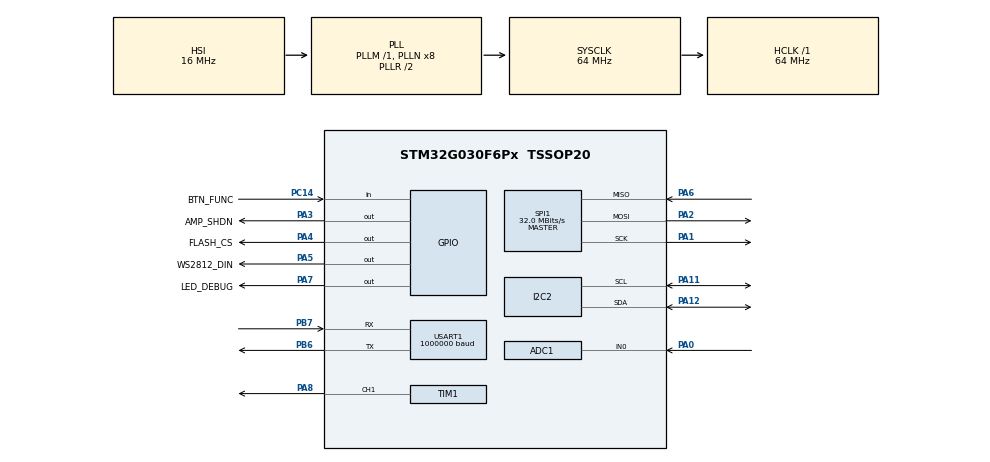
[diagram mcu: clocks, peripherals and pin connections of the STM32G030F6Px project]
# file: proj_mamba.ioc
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ADC1.Channel-0\#ChannelRegularConversion=ADC_CHANNEL_0
ADC1.NbrOfConversionFlag=1
ADC1.Rank-0\#ChannelRegularConversion=1
ADC1.SamplingTime-0\#ChannelRegularConversion=ADC_SAMPLINGTIME_COMMON_1
ADC1.SamplingTimeCommon1=ADC_SAMPLETIME_160CYCLES_5
ADC1.SelectedChannel=ADC_CHANNEL_0
ADC1.master=1
Dma.Request0=SPI1_RX
Dma.Request1=SPI1_TX
Dma.Request2=USART1_RX
Dma.Request3=USART1_TX
Dma.SPI1_RX.0.Direction=DMA_PERIPH_TO_MEMORY
Dma.SPI1_RX.0.EventEnable=DISABLE
Dma.SPI1_RX.0.Instance=DMA1_Channel1
Dma.SPI1_RX.0.MemDataAlignment=DMA_MDATAALIGN_BYTE
Dma.SPI1_RX.0.MemInc=DMA_MINC_ENABLE
Dma.SPI1_RX.0.Mode=DMA_NORMAL
Dma.SPI1_RX.0.PeriphDataAlignment=DMA_PDATAALIGN_BYTE
Dma.SPI1_RX.0.PeriphInc=DMA_PINC_DISABLE
Dma.SPI1_RX.0.Polarity=HAL_DMAMUX_REQ_GEN_RISING
Dma.SPI1_RX.0.Priority=DMA_PRIORITY_LOW
Dma.SPI1_RX.0.RequestNumber=1
Dma.SPI1_RX.0.SignalID=NONE
Dma.SPI1_RX.0.SyncEnable=DISABLE
Dma.SPI1_RX.0.SyncPolarity=HAL_DMAMUX_SYNC_NO_EVENT
Dma.SPI1_RX.0.SyncRequestNumber=1
Dma.SPI1_RX.0.SyncSignalID=NONE
Dma.SPI1_TX.1.Direction=DMA_MEMORY_TO_PERIPH
Dma.SPI1_TX.1.EventEnable=DISABLE
Dma.SPI1_TX.1.Instance=DMA1_Channel2
Dma.SPI1_TX.1.MemDataAlignment=DMA_MDATAALIGN_BYTE
Dma.SPI1_TX.1.MemInc=DMA_MINC_ENABLE
Dma.SPI1_TX.1.Mode=DMA_NORMAL
Dma.SPI1_TX.1.PeriphDataAlignment=DMA_PDATAALIGN_BYTE
Dma.SPI1_TX.1.PeriphInc=DMA_PINC_DISABLE
Dma.SPI1_TX.1.Polarity=HAL_DMAMUX_REQ_GEN_RISING
Dma.SPI1_TX.1.Priority=DMA_PRIORITY_LOW
Dma.SPI1_TX.1.RequestNumber=1
Dma.SPI1_TX.1.SignalID=NONE
Dma.SPI1_TX.1.SyncEnable=DISABLE
Dma.SPI1_TX.1.SyncPolarity=HAL_DMAMUX_SYNC_NO_EVENT
Dma.SPI1_TX.1.SyncRequestNumber=1
Dma.SPI1_TX.1.SyncSignalID=NONE
Dma.USART1_RX.2.Direction=DMA_PERIPH_TO_MEMORY
Dma.USART1_RX.2.EventEnable=DISABLE
Dma.USART1_RX.2.Instance=DMA1_Channel3
Dma.USART1_RX.2.MemDataAlignment=DMA_MDATAALIGN_BYTE
Dma.USART1_RX.2.MemInc=DMA_MINC_ENABLE
Dma.USART1_RX.2.Mode=DMA_NORMAL
Dma.USART1_RX.2.PeriphDataAlignment=DMA_PDATAALIGN_BYTE
Dma.USART1_RX.2.PeriphInc=DMA_PINC_DISABLE
Dma.USART1_RX.2.Polarity=HAL_DMAMUX_REQ_GEN_RISING
Dma.USART1_RX.2.Priority=DMA_PRIORITY_LOW
Dma.USART1_RX.2.RequestNumber=1
Dma.USART1_RX.2.SignalID=NONE
Dma.USART1_RX.2.SyncEnable=DISABLE
Dma.USART1_RX.2.SyncPolarity=HAL_DMAMUX_SYNC_NO_EVENT
Dma.USART1_RX.2.SyncRequestNumber=1
Dma.USART1_RX.2.SyncSignalID=NONE
Dma.USART1_TX.3.Direction=DMA_MEMORY_TO_PERIPH
Dma.USART1_TX.3.EventEnable=DISABLE
Dma.USART1_TX.3.Instance=DMA1_Channel4
Dma.USART1_TX.3.MemDataAlignment=DMA_MDATAALIGN_BYTE
Dma.USART1_TX.3.MemInc=DMA_MINC_ENABLE
Dma.USART1_TX.3.Mode=DMA_NORMAL
Dma.USART1_TX.3.PeriphDataAlignment=DMA_PDATAALIGN_BYTE
Dma.USART1_TX.3.PeriphInc=DMA_PINC_DISABLE
Dma.USART1_TX.3.Polarity=HAL_DMAMUX_REQ_GEN_RISING
Dma.USART1_TX.3.Priority=DMA_PRIORITY_LOW
Dma.USART1_TX.3.RequestNumber=1
Dma.USART1_TX.3.SignalID=NONE
Dma.USART1_TX.3.SyncEnable=DISABLE
Dma.USART1_TX.3.SyncPolarity=HAL_DMAMUX_SYNC_NO_EVENT
Dma.USART1_TX.3.SyncRequestNumber=1
Dma.USART1_TX.3.SyncSignalID=NONE
I2C2.Timing=0x10B17DB5
Mcu.Family=STM32G0
Mcu.Name=STM32G030F6Px
Mcu.Package=TSSOP20
NVIC.ADC1_IRQn=true\:0\:0\:false\:false\:true\:true\:true\:true
NVIC.DMA1_Ch4_5_DMAMUX1_OVR_IRQn=true\:0\:0\:false\:false\:true\:false\:true\:true
NVIC.DMA1_Channel1_IRQn=true\:0\:0\:false\:false\:true\:false\:true\:true
NVIC.DMA1_Channel2_3_IRQn=true\:0\:0\:false\:false\:true\:false\:true\:true
NVIC.I2C2_IRQn=true\:0\:0\:false\:false\:true\:true\:true\:true
NVIC.SPI1_IRQn=true\:0\:0\:false\:false\:true\:true\:true\:true
NVIC.TIM1_BRK_UP_TRG_COM_IRQn=true\:0\:0\:false\:false\:true\:true\:true\:true
NVIC.USART1_IRQn=true\:0\:0\:false\:false\:true\:true\:true\:true
PA0.Mode=IN0
PA0.Signal=ADC1_IN0
PA1.Mode=Full_Duplex_Master
PA1.Signal=SPI1_SCK
PA11\ [PA9].Mode=I2C
PA11\ [PA9].Signal=I2C2_SCL
PA12\ [PA10].Mode=I2C
PA12\ [PA10].Signal=I2C2_SDA
PA13.Mode=Serial_Wire
PA13.Signal=SYS_SWDIO
PA14-BOOT0.Mode=Serial_Wire
PA14-BOOT0.Signal=SYS_SWCLK
PA14-BOOT0__PA15.StandardMode=true
PA2.Mode=Full_Duplex_Master
PA2.Signal=SPI1_MOSI
PA3.GPIO_Label=AMP_SHDN
PA3.Signal=GPIO_Output
PA4.GPIO_Label=FLASH_CS
PA4.PinState=GPIO_PIN_SET
PA4.Signal=GPIO_Output
PA5.GPIO_Label=WS2812_DIN
PA5.GPIO_Speed=GPIO_SPEED_FREQ_VERY_HIGH
PA5.Signal=GPIO_Output
PA6.Mode=Full_Duplex_Master
PA6.Signal=SPI1_MISO
PA7.GPIO_Label=LED_DEBUG
PA7.Signal=GPIO_Output
PA8.Signal=S_TIM1_CH1
PB0__PB1__PB2__PA8.StandardMode=true
PB3__PB4__PB5__PB6.StandardMode=true
PB6.Mode=Asynchronous
PB6.Signal=USART1_TX
PB7.Mode=Asynchronous
PB7.Signal=USART1_RX
PB7__PB8.StandardMode=true
PC14-OSC32_IN\ (PC14).GPIO_Label=BTN_FUNC
PC14-OSC32_IN\ (PC14).GPIO_PuPd=GPIO_PULLUP
PC14-OSC32_IN\ (PC14).Signal=GPIO_Input
PC14-OSC32_IN\ (PC14)__PB9.StandardMode=true
ProjectManager.HeapSize=0x200
ProjectManager.StackSize=0x400
ProjectManager.TargetToolchain=CMake
RCC.ADCFreq_Value=64000000
RCC.AHBFreq_Value=64000000
RCC.CortexFreq_Value=64000000
RCC.EXTERNAL_CLOCK_VALUE=12288000
RCC.HCLKFreq_Value=64000000
RCC.HSE_VALUE=8000000
RCC.HSI_VALUE=16000000
RCC.LSE_VALUE=32768
RCC.SYSCLKFreq_VALUE=64000000
RCC.SYSCLKSource=RCC_SYSCLKSOURCE_PLLCLK
RCC.VCOOutputFreq_Value=128000000
SH.S_TIM1_CH1.0=TIM1_CH1,PWM Generation1 CH1
SPI1.CalculateBaudRate=32.0 MBits/s
SPI1.Direction=SPI_DIRECTION_2LINES
SPI1.Mode=SPI_MODE_MASTER
SPI1.VirtualType=VM_MASTER
TIM1.AutoReloadPreload=TIM_AUTORELOAD_PRELOAD_ENABLE
TIM1.Channel-PWM\ Generation1\ CH1=TIM_CHANNEL_1
TIM1.Period=249
TIM1.RepetitionCounter=7
USART1.BaudRate=1000000
USART1.VirtualMode-Asynchronous=VM_ASYNC
board=custom

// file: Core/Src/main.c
/* USER CODE BEGIN Header */
/**
  ******************************************************************************
  * @file           : main.c
  * @brief          : Main program body
  ******************************************************************************
  * @attention
  *
  * Copyright (c) 2026 STMicroelectronics.
  * All rights reserved.
  *
  * This software is licensed under terms that can be found in the LICENSE file
  * in the root directory of this software component.
  * If no LICENSE file comes with this software, it is provided AS-IS.
  *
  ******************************************************************************
  */
/* USER CODE END Header */
#include "main.h"

/* USER CODE BEGIN Includes */
#include "user_bridge.h"
/* USER CODE END Includes */

ADC_HandleTypeDef hadc1;

I2C_HandleTypeDef hi2c2;

SPI_HandleTypeDef hspi1;
DMA_HandleTypeDef hdma_spi1_rx;
DMA_HandleTypeDef hdma_spi1_tx;

TIM_HandleTypeDef htim1;

UART_HandleTypeDef huart1;
DMA_HandleTypeDef hdma_usart1_rx;
DMA_HandleTypeDef hdma_usart1_tx;

void SystemClock_Config(void);
static void MX_GPIO_Init(void);
static void MX_DMA_Init(void);
static void MX_ADC1_Init(void);
static void MX_I2C2_Init(void);
static void MX_SPI1_Init(void);
static void MX_TIM1_Init(void);
static void MX_USART1_UART_Init(void);

int main(void)
{

  /* MCU Configuration--------------------------------------------------------*/

  /* Reset of all peripherals, Initializes the Flash interface and the Systick. */
  HAL_Init();

  /* Configure the system clock */
  SystemClock_Config();

  /* Initialize all configured peripherals */
  MX_GPIO_Init();
  MX_DMA_Init();
  MX_ADC1_Init();
  MX_I2C2_Init();
  MX_SPI1_Init();
  MX_TIM1_Init();
  MX_USART1_UART_Init();
  /* USER CODE BEGIN 2 */
  User_App_Init();
  /* USER CODE END 2 */

  /* Infinite loop */
  while (1)
  {

    /* USER CODE BEGIN 3 */
    User_App_Loop();
  }
  /* USER CODE END 3 */
}

void SystemClock_Config(void)
{
  RCC_OscInitTypeDef RCC_OscInitStruct = {0};
  RCC_ClkInitTypeDef RCC_ClkInitStruct = {0};

  /** Configure the main internal regulator output voltage
  */
  HAL_PWREx_ControlVoltageScaling(PWR_REGULATOR_VOLTAGE_SCALE1);

  /** Initializes the RCC Oscillators according to the specified parameters
  * in the RCC_OscInitTypeDef structure.
  */
  RCC_OscInitStruct.OscillatorType = RCC_OSCILLATORTYPE_HSI;
  RCC_OscInitStruct.HSIState = RCC_HSI_ON;
  RCC_OscInitStruct.HSIDiv = RCC_HSI_DIV1;
  RCC_OscInitStruct.HSICalibrationValue = RCC_HSICALIBRATION_DEFAULT;
  RCC_OscInitStruct.PLL.PLLState = RCC_PLL_ON;
  RCC_OscInitStruct.PLL.PLLSource = RCC_PLLSOURCE_HSI;
  RCC_OscInitStruct.PLL.PLLM = RCC_PLLM_DIV1;
  RCC_OscInitStruct.PLL.PLLN = 8;
  RCC_OscInitStruct.PLL.PLLP = RCC_PLLP_DIV2;
  RCC_OscInitStruct.PLL.PLLR = RCC_PLLR_DIV2;
  if (HAL_RCC_OscConfig(&RCC_OscInitStruct) != HAL_OK)
  {
    Error_Handler();
  }

  /** Initializes the CPU, AHB and APB buses clocks
  */
  RCC_ClkInitStruct.ClockType = RCC_CLOCKTYPE_HCLK|RCC_CLOCKTYPE_SYSCLK
                              |RCC_CLOCKTYPE_PCLK1;
  RCC_ClkInitStruct.SYSCLKSource = RCC_SYSCLKSOURCE_PLLCLK;
  RCC_ClkInitStruct.AHBCLKDivider = RCC_SYSCLK_DIV1;
  RCC_ClkInitStruct.APB1CLKDivider = RCC_HCLK_DIV1;

  if (HAL_RCC_ClockConfig(&RCC_ClkInitStruct, FLASH_LATENCY_2) != HAL_OK)
  {
    Error_Handler();
  }
}

static void MX_ADC1_Init(void)
{

  ADC_ChannelConfTypeDef sConfig = {0};

  /** Configure the global features of the ADC (Clock, Resolution, Data Alignment and number of conversion)
  */
  hadc1.Instance = ADC1;
  hadc1.Init.ClockPrescaler = ADC_CLOCK_SYNC_PCLK_DIV2;
  hadc1.Init.Resolution = ADC_RESOLUTION_12B;
  hadc1.Init.DataAlign = ADC_DATAALIGN_RIGHT;
  hadc1.Init.ScanConvMode = ADC_SCAN_DISABLE;
  hadc1.Init.EOCSelection = ADC_EOC_SINGLE_CONV;
  hadc1.Init.LowPowerAutoWait = DISABLE;
  hadc1.Init.LowPowerAutoPowerOff = DISABLE;
  hadc1.Init.ContinuousConvMode = DISABLE;
  hadc1.Init.NbrOfConversion = 1;
  hadc1.Init.DiscontinuousConvMode = DISABLE;
  hadc1.Init.ExternalTrigConv = ADC_SOFTWARE_START;
  hadc1.Init.ExternalTrigConvEdge = ADC_EXTERNALTRIGCONVEDGE_NONE;
  hadc1.Init.DMAContinuousRequests = DISABLE;
  hadc1.Init.Overrun = ADC_OVR_DATA_PRESERVED;
  hadc1.Init.SamplingTimeCommon1 = ADC_SAMPLETIME_160CYCLES_5;
  hadc1.Init.SamplingTimeCommon2 = ADC_SAMPLETIME_1CYCLE_5;
  hadc1.Init.OversamplingMode = DISABLE;
  hadc1.Init.TriggerFrequencyMode = ADC_TRIGGER_FREQ_HIGH;
  if (HAL_ADC_Init(&hadc1) != HAL_OK)
  {
    Error_Handler();
  }

  /** Configure Regular Channel
  */
  sConfig.Channel = ADC_CHANNEL_0;
  sConfig.Rank = ADC_REGULAR_RANK_1;
  sConfig.SamplingTime = ADC_SAMPLINGTIME_COMMON_1;
  if (HAL_ADC_ConfigChannel(&hadc1, &sConfig) != HAL_OK)
  {
    Error_Handler();
  }

}

static void MX_I2C2_Init(void)
{

  hi2c2.Instance = I2C2;
  hi2c2.Init.Timing = 0x10B17DB5;
  hi2c2.Init.OwnAddress1 = 0;
  hi2c2.Init.AddressingMode = I2C_ADDRESSINGMODE_7BIT;
  hi2c2.Init.DualAddressMode = I2C_DUALADDRESS_DISABLE;
  hi2c2.Init.OwnAddress2 = 0;
  hi2c2.Init.OwnAddress2Masks = I2C_OA2_NOMASK;
  hi2c2.Init.GeneralCallMode = I2C_GENERALCALL_DISABLE;
  hi2c2.Init.NoStretchMode = I2C_NOSTRETCH_DISABLE;
  if (HAL_I2C_Init(&hi2c2) != HAL_OK)
  {
    Error_Handler();
  }

  /** Configure Analogue filter
  */
  if (HAL_I2CEx_ConfigAnalogFilter(&hi2c2, I2C_ANALOGFILTER_ENABLE) != HAL_OK)
  {
    Error_Handler();
  }

  /** Configure Digital filter
  */
  if (HAL_I2CEx_ConfigDigitalFilter(&hi2c2, 0) != HAL_OK)
  {
    Error_Handler();
  }

}

static void MX_SPI1_Init(void)
{

  /* SPI1 parameter configuration*/
  hspi1.Instance = SPI1;
  hspi1.Init.Mode = SPI_MODE_MASTER;
  hspi1.Init.Direction = SPI_DIRECTION_2LINES;
  hspi1.Init.DataSize = SPI_DATASIZE_8BIT;
  hspi1.Init.CLKPolarity = SPI_POLARITY_LOW;
  hspi1.Init.CLKPhase = SPI_PHASE_1EDGE;
  hspi1.Init.NSS = SPI_NSS_SOFT;
  hspi1.Init.BaudRatePrescaler = SPI_BAUDRATEPRESCALER_2;
  hspi1.Init.FirstBit = SPI_FIRSTBIT_MSB;
  hspi1.Init.TIMode = SPI_TIMODE_DISABLE;
  hspi1.Init.CRCCalculation = SPI_CRCCALCULATION_DISABLE;
  hspi1.Init.CRCPolynomial = 7;
  hspi1.Init.CRCLength = SPI_CRC_LENGTH_DATASIZE;
  hspi1.Init.NSSPMode = SPI_NSS_PULSE_DISABLE;
  if (HAL_SPI_Init(&hspi1) != HAL_OK)
  {
    Error_Handler();
  }

}

static void MX_TIM1_Init(void)
{

  TIM_MasterConfigTypeDef sMasterConfig = {0};
  TIM_OC_InitTypeDef sConfigOC = {0};
  TIM_BreakDeadTimeConfigTypeDef sBreakDeadTimeConfig = {0};

  htim1.Instance = TIM1;
  htim1.Init.Prescaler = 0;
  htim1.Init.CounterMode = TIM_COUNTERMODE_UP;
  htim1.Init.Period = 249;
  htim1.Init.ClockDivision = TIM_CLOCKDIVISION_DIV1;
  htim1.Init.RepetitionCounter = 7;
  htim1.Init.AutoReloadPreload = TIM_AUTORELOAD_PRELOAD_ENABLE;
  if (HAL_TIM_PWM_Init(&htim1) != HAL_OK)
  {
    Error_Handler();
  }
  sMasterConfig.MasterOutputTrigger = TIM_TRGO_RESET;
  sMasterConfig.MasterOutputTrigger2 = TIM_TRGO2_RESET;
  sMasterConfig.MasterSlaveMode = TIM_MASTERSLAVEMODE_DISABLE;
  if (HAL_TIMEx_MasterConfigSynchronization(&htim1, &sMasterConfig) != HAL_OK)
  {
    Error_Handler();
  }
  sConfigOC.OCMode = TIM_OCMODE_PWM1;
  sConfigOC.Pulse = 0;
  sConfigOC.OCPolarity = TIM_OCPOLARITY_HIGH;
  sConfigOC.OCNPolarity = TIM_OCNPOLARITY_HIGH;
  sConfigOC.OCFastMode = TIM_OCFAST_DISABLE;
  sConfigOC.OCIdleState = TIM_OCIDLESTATE_RESET;
  sConfigOC.OCNIdleState = TIM_OCNIDLESTATE_RESET;
  if (HAL_TIM_PWM_ConfigChannel(&htim1, &sConfigOC, TIM_CHANNEL_1) != HAL_OK)
  {
    Error_Handler();
  }
  sBreakDeadTimeConfig.OffStateRunMode = TIM_OSSR_DISABLE;
  sBreakDeadTimeConfig.OffStateIDLEMode = TIM_OSSI_DISABLE;
  sBreakDeadTimeConfig.LockLevel = TIM_LOCKLEVEL_OFF;
  sBreakDeadTimeConfig.DeadTime = 0;
  sBreakDeadTimeConfig.BreakState = TIM_BREAK_DISABLE;
  sBreakDeadTimeConfig.BreakPolarity = TIM_BREAKPOLARITY_HIGH;
  sBreakDeadTimeConfig.BreakFilter = 0;
  sBreakDeadTimeConfig.BreakAFMode = TIM_BREAK_AFMODE_INPUT;
  sBreakDeadTimeConfig.Break2State = TIM_BREAK2_DISABLE;
  sBreakDeadTimeConfig.Break2Polarity = TIM_BREAK2POLARITY_HIGH;
  sBreakDeadTimeConfig.Break2Filter = 0;
  sBreakDeadTimeConfig.Break2AFMode = TIM_BREAK_AFMODE_INPUT;
  sBreakDeadTimeConfig.AutomaticOutput = TIM_AUTOMATICOUTPUT_DISABLE;
  if (HAL_TIMEx_ConfigBreakDeadTime(&htim1, &sBreakDeadTimeConfig) != HAL_OK)
  {
    Error_Handler();
  }
  HAL_TIM_MspPostInit(&htim1);

}

static void MX_USART1_UART_Init(void)
{

  huart1.Instance = USART1;
  huart1.Init.BaudRate = 1000000;
  huart1.Init.WordLength = UART_WORDLENGTH_8B;
  huart1.Init.StopBits = UART_STOPBITS_1;
  huart1.Init.Parity = UART_PARITY_NONE;
  huart1.Init.Mode = UART_MODE_TX_RX;
  huart1.Init.HwFlowCtl = UART_HWCONTROL_NONE;
  huart1.Init.OverSampling = UART_OVERSAMPLING_16;
  huart1.Init.OneBitSampling = UART_ONE_BIT_SAMPLE_DISABLE;
  huart1.Init.ClockPrescaler = UART_PRESCALER_DIV1;
  huart1.AdvancedInit.AdvFeatureInit = UART_ADVFEATURE_NO_INIT;
  if (HAL_UART_Init(&huart1) != HAL_OK)
  {
    Error_Handler();
  }
  if (HAL_UARTEx_SetTxFifoThreshold(&huart1, UART_TXFIFO_THRESHOLD_1_8) != HAL_OK)
  {
    Error_Handler();
  }
  if (HAL_UARTEx_SetRxFifoThreshold(&huart1, UART_RXFIFO_THRESHOLD_1_8) != HAL_OK)
  {
    Error_Handler();
  }
  if (HAL_UARTEx_DisableFifoMode(&huart1) != HAL_OK)
  {
    Error_Handler();
  }

}

static void MX_DMA_Init(void)
{

  /* DMA controller clock enable */
  __HAL_RCC_DMA1_CLK_ENABLE();

  /* DMA interrupt init */
  /* DMA1_Channel1_IRQn interrupt configuration */
  HAL_NVIC_SetPriority(DMA1_Channel1_IRQn, 0, 0);
  HAL_NVIC_EnableIRQ(DMA1_Channel1_IRQn);
  /* DMA1_Channel2_3_IRQn interrupt configuration */
  HAL_NVIC_SetPriority(DMA1_Channel2_3_IRQn, 0, 0);
  HAL_NVIC_EnableIRQ(DMA1_Channel2_3_IRQn);
  /* DMA1_Ch4_5_DMAMUX1_OVR_IRQn interrupt configuration */
  HAL_NVIC_SetPriority(DMA1_Ch4_5_DMAMUX1_OVR_IRQn, 0, 0);
  HAL_NVIC_EnableIRQ(DMA1_Ch4_5_DMAMUX1_OVR_IRQn);

}

static void MX_GPIO_Init(void)
{
  GPIO_InitTypeDef GPIO_InitStruct = {0};

  /* GPIO Ports Clock Enable */
  __HAL_RCC_GPIOB_CLK_ENABLE();
  __HAL_RCC_GPIOC_CLK_ENABLE();
  __HAL_RCC_GPIOA_CLK_ENABLE();

  /*Configure GPIO pin Output Level */
  HAL_GPIO_WritePin(GPIOA, AMP_SHDN_Pin|WS2812_DIN_Pin|LED_DEBUG_Pin, GPIO_PIN_RESET);

  /*Configure GPIO pin Output Level */
  HAL_GPIO_WritePin(FLASH_CS_GPIO_Port, FLASH_CS_Pin, GPIO_PIN_SET);

  /*Configure GPIO pin : BTN_FUNC_Pin */
  GPIO_InitStruct.Pin = BTN_FUNC_Pin;
  GPIO_InitStruct.Mode = GPIO_MODE_INPUT;
  GPIO_InitStruct.Pull = GPIO_PULLUP;
  HAL_GPIO_Init(BTN_FUNC_GPIO_Port, &GPIO_InitStruct);

  /*Configure GPIO pins : AMP_SHDN_Pin FLASH_CS_Pin LED_DEBUG_Pin */
  GPIO_InitStruct.Pin = AMP_SHDN_Pin|FLASH_CS_Pin|LED_DEBUG_Pin;
  GPIO_InitStruct.Mode = GPIO_MODE_OUTPUT_PP;
  GPIO_InitStruct.Pull = GPIO_NOPULL;
  GPIO_InitStruct.Speed = GPIO_SPEED_FREQ_LOW;
  HAL_GPIO_Init(GPIOA, &GPIO_InitStruct);

  /*Configure GPIO pin : WS2812_DIN_Pin */
  GPIO_InitStruct.Pin = WS2812_DIN_Pin;
  GPIO_InitStruct.Mode = GPIO_MODE_OUTPUT_PP;
  GPIO_InitStruct.Pull = GPIO_NOPULL;
  GPIO_InitStruct.Speed = GPIO_SPEED_FREQ_VERY_HIGH;
  HAL_GPIO_Init(WS2812_DIN_GPIO_Port, &GPIO_InitStruct);

}

/* USER CODE BEGIN 4 */

/**
 * @brief TIM 周期溢出中断回调 (音频 PWM 更新)
 */
void HAL_TIM_PeriodElapsedCallback(TIM_HandleTypeDef *htim)
{
  User_TIM_PeriodElapsedCallback(htim);
}

/**
 * @brief UART 接收完成回调 (普通 DMA 接收，收到指定长度触发)
 */
void HAL_UART_RxCpltCallback(UART_HandleTypeDef *huart)
{
  User_UART_RxCpltCallback(huart);
}

/* USER CODE END 4 */

void Error_Handler(void)
{
  __disable_irq();
  while (1)
  {
  }
}
